AUTOSAR XML (schema 314)
package /ComponentType
  internal behavior Sa_CDDInterface_InternalBehavior: component=Sa_CDDInterface
    5 x timing event:
      CDDInterface_Init1_InitEvent: start-on-event=CDDInterface_Init1, period=0
      CDDInterface_Init2_InitEvent: start-on-event=CDDInterface_Init2, period=0
      TMT_CDDInterface_Per1: start-on-event=CDDInterface_Per1, period=0.002
      TMT_CDDInterface_Per2: start-on-event=CDDInterface_Per2, period=0.002
      TMT_CDDInterface_Per4: start-on-event=CDDInterface_Per4, period=0.01
    operation invoked event OIT_MtrVelCDDInterface_GetMtrVelSignals_MtrVelCDDInterface_GetMtrVelSignals: start-on-event=MtrVelCDDInterface_GetMtrVelSignals, operation=MtrVelCDDInterface.GetMtrVelSignals
    port-api-options:
      enable-take-address=false, indirect-api=false, port=ADCMtrCurr1
      enable-take-address=false, indirect-api=false, port=ADCMtrCurr2
      enable-take-address=false, indirect-api=false, port=CDDPorts
      enable-take-address=false, indirect-api=false, port=CommOffset
      enable-take-address=false, indirect-api=false, port=CorrMtrCurrPosition
      enable-take-address=false, indirect-api=false, port=CorrMtrPosElec
      enable-take-address=false, indirect-api=false, port=Cos1Theta
      enable-take-address=false, indirect-api=false, port=DampingSrlComSvcDft
      enable-take-address=false, indirect-api=false, port=DaxIntegralGain_IPM
      enable-take-address=false, indirect-api=false, port=DaxIntegralGain_SPM
      enable-take-address=false, indirect-api=false, port=DaxPropotionalGain_IPM
      enable-take-address=false, indirect-api=false, port=DaxPropotionalGain_SPM
      enable-take-address=false, indirect-api=false, port=DftAsstTbl
      enable-take-address=false, indirect-api=false, port=DrivingDynSrlComSvcDft
      enable-take-address=false, indirect-api=false, port=DutyCycleSmall
      enable-take-address=false, indirect-api=false, port=DwnldAsstGain
      enable-take-address=false, indirect-api=false, port=EngONSrlComSvcDft
      enable-take-address=false, indirect-api=false, port=EOTImpactSrlComSvcDft
      enable-take-address=false, indirect-api=false, port=EOTThermalSrlComSvcDft
      enable-take-address=false, indirect-api=false, port=EstKe
      enable-take-address=false, indirect-api=false, port=ExpectedOnTimeA
      enable-take-address=false, indirect-api=false, port=ExpectedOnTimeB
      enable-take-address=false, indirect-api=false, port=ExpectedOnTimeC
      enable-take-address=false, indirect-api=false, port=FETFaultPhase
      enable-take-address=false, indirect-api=false, port=FETFaultType
      enable-take-address=false, indirect-api=false, port=FreqDepDmpSrlComSvcDft
      enable-take-address=false, indirect-api=false, port=FricLrnSrlComSvcDft
      enable-take-address=false, indirect-api=false, port=HysAddSrlComSvcDft
      enable-take-address=false, indirect-api=false, port=HystCompSrlComSvcDft
      enable-take-address=false, indirect-api=false, port=IgnCnt
      enable-take-address=false, indirect-api=false, port=KinIntDiagSrlComSvcDft
      enable-take-address=false, indirect-api=false, port=LimitSrlComSvcDft
      enable-take-address=false, indirect-api=false, port=LRPRPhaseadvanceCaptured
      enable-take-address=false, indirect-api=false, port=MeasuredOnTimeA
      enable-take-address=false, indirect-api=false, port=MeasuredOnTimeB
      enable-take-address=false, indirect-api=false, port=MeasuredOnTimeC
      enable-take-address=false, indirect-api=false, port=MEC
      enable-take-address=false, indirect-api=false, port=MfgDiagInhibit
      enable-take-address=false, indirect-api=false, port=ModIdxFinal
      enable-take-address=false, indirect-api=false, port=ModIdxSrlComSvcDft
      enable-take-address=false, indirect-api=false, port=MRFMtrVel
      enable-take-address=false, indirect-api=false, port=MtrCurr1TempOffset
      enable-take-address=false, indirect-api=false, port=MtrCurr2TempOffset
      enable-take-address=false, indirect-api=false, port=MtrCurrDax
      enable-take-address=false, indirect-api=false, port=MtrCurrDaxRef
      enable-take-address=false, indirect-api=false, port=MtrCurrDaxRef_IPM
      enable-take-address=false, indirect-api=false, port=MtrCurrDaxRef_SPM
      enable-take-address=false, indirect-api=false, port=MtrCurrK1
      enable-take-address=false, indirect-api=false, port=MtrCurrK2
      enable-take-address=false, indirect-api=false, port=MtrCurrQax
      enable-take-address=false, indirect-api=false, port=MtrCurrQax12Mag
      enable-take-address=false, indirect-api=false, port=MtrCurrQax12Ph
      enable-take-address=false, indirect-api=false, port=MtrCurrQax6Mag
      enable-take-address=false, indirect-api=false, port=MtrCurrQax6Ph
      enable-take-address=false, indirect-api=false, port=MtrCurrQaxFinalRef
      enable-take-address=false, indirect-api=false, port=MtrCurrQaxRef_IPM
      enable-take-address=false, indirect-api=false, port=MtrCurrQaxRef_SPM
      enable-take-address=false, indirect-api=false, port=MtrElecMechPolarity
      enable-take-address=false, indirect-api=false, port=MtrParmNrmLrnSrlComSvcDft
      enable-take-address=false, indirect-api=false, port=MtrPosComputationDelay_IPM
      enable-take-address=false, indirect-api=false, port=MtrPosComputationDelay_SPM
      enable-take-address=false, indirect-api=false, port=MtrPosElec
      enable-take-address=false, indirect-api=false, port=MtrPosMech
      enable-take-address=false, indirect-api=false, port=MtrRevCntr
      enable-take-address=false, indirect-api=false, port=MtrTrqCmdSign_IPM
      enable-take-address=false, indirect-api=false, port=MtrTrqCmdSign_SPM
      enable-take-address=false, indirect-api=false, port=MtrVelCDDInterface
      enable-take-address=false, indirect-api=false, port=MtrVelNrmLrnSrlComSvcDft
      enable-take-address=false, indirect-api=false, port=MtrVoltDax
      enable-take-address=false, indirect-api=false, port=MtrVoltDaxFF_IPM
      enable-take-address=false, indirect-api=false, port=MtrVoltDaxFF_SPM
      enable-take-address=false, indirect-api=false, port=MtrVoltQax
      enable-take-address=false, indirect-api=false, port=MtrVoltQaxFF_IPM
      enable-take-address=false, indirect-api=false, port=MtrVoltQaxFF_SPM
      enable-take-address=false, indirect-api=false, port=MultIgnSrlComSvcDft
      enable-take-address=false, indirect-api=false, port=ParkAstSrlComSvcDft
      enable-take-address=false, indirect-api=false, port=PhsReasA
      enable-take-address=false, indirect-api=false, port=PhsReasB
      enable-take-address=false, indirect-api=false, port=PhsReasC
      enable-take-address=false, indirect-api=false, port=PullCompSrlComSvcDft
      enable-take-address=false, indirect-api=false, port=QaxIntegralGain_IPM
      enable-take-address=false, indirect-api=false, port=QaxIntegralGain_SPM
      enable-take-address=false, indirect-api=false, port=QaxPropotionalGain_IPM
      enable-take-address=false, indirect-api=false, port=QaxPropotionalGain_SPM
      enable-take-address=false, indirect-api=false, port=ReturnSrlComSvcDft
      enable-take-address=false, indirect-api=false, port=RxMsgsSrlComSvcDft
      enable-take-address=false, indirect-api=false, port=Sin1Theta
      enable-take-address=false, indirect-api=false, port=SrlComSvcDft
      enable-take-address=false, indirect-api=false, port=SWDutyCycleA
      enable-take-address=false, indirect-api=false, port=SWDutyCycleB
      enable-take-address=false, indirect-api=false, port=SWDutyCycleC
      enable-take-address=false, indirect-api=false, port=SysCCorrectedMtrPos
      enable-take-address=false, indirect-api=false, port=SystemState
      enable-take-address=false, indirect-api=false, port=ThermalDCSrlComSvcDft
      enable-take-address=false, indirect-api=false, port=TOEOLDisable
      enable-take-address=false, indirect-api=false, port=TrqRmpSrlComSvcDft
      enable-take-address=false, indirect-api=false, port=Vecu
      enable-take-address=false, indirect-api=false, port=WhlImbRejSrlComSvcDft
      enable-take-address=false, indirect-api=false, port=WIREnabled
    6 x runnable:
      CDDInterface_Init1
        data read access READ_MtrElecMechPolarity_Cnt_s08: data-element=MtrElecMechPolarity.Cnt_s08
        data write access WRITE_IgnCnt_Cnt_u16: data-element=IgnCnt.Cnt_u16
        data write access WRITE_MEC_Cnt_enum: data-element=MEC.Cnt_enum
        sync call SC_CDDPorts_ApplyMtrElecMechPol: operation=CDDPorts.ApplyMtrElecMechPol, timeout=0
      CDDInterface_Init2
      CDDInterface_Per1
        33 x data write access:
          WRITE_ADCMtrCurr1_Volts_f32: data-element=ADCMtrCurr1.Volts_f32
          WRITE_ADCMtrCurr2_Volts_f32: data-element=ADCMtrCurr2.Volts_f32
          WRITE_CorrMtrCurrPosition_Rev_f32: data-element=CorrMtrCurrPosition.Rev_f32
          WRITE_CorrMtrPosElec_Rev_f32: data-element=CorrMtrPosElec.Rev_f32
          WRITE_Cos1Theta_Volts_f32: data-element=Cos1Theta.Volts_f32
          WRITE_DutyCycleSmall_Cnt_u16: data-element=DutyCycleSmall.Cnt_u16
          WRITE_ExpectedOnTimeA_Cnt_u32: data-element=ExpectedOnTimeA.Cnt_u32
          WRITE_ExpectedOnTimeB_Cnt_u32: data-element=ExpectedOnTimeB.Cnt_u32
          WRITE_ExpectedOnTimeC_Cnt_u32: data-element=ExpectedOnTimeC.Cnt_u32
          WRITE_LRPRPhaseadvanceCaptured_Cnt_s16: data-element=LRPRPhaseadvanceCaptured.Cnt_s16
          WRITE_MeasuredOnTimeA_Cnt_u32: data-element=MeasuredOnTimeA.Cnt_u32
          WRITE_MeasuredOnTimeB_Cnt_u32: data-element=MeasuredOnTimeB.Cnt_u32
          WRITE_MeasuredOnTimeC_Cnt_u32: data-element=MeasuredOnTimeC.Cnt_u32
          WRITE_ModIdxFinal_Uls_f32: data-element=ModIdxFinal.Uls_f32
          WRITE_MtrCurrDax_Amp_f32: data-element=MtrCurrDax.Amp_f32
          WRITE_MtrCurrDaxRef_Amp_f32: data-element=MtrCurrDaxRef.Amp_f32
          WRITE_MtrCurrK1_Amp_f32: data-element=MtrCurrK1.Amp_f32
          WRITE_MtrCurrK2_Amp_f32: data-element=MtrCurrK2.Amp_f32
          WRITE_MtrCurrQax_Amp_f32: data-element=MtrCurrQax.Amp_f32
          WRITE_MtrCurrQaxFinalRef_Amp_f32: data-element=MtrCurrQaxFinalRef.Amp_f32
          WRITE_MtrPosElec_Rev_f32: data-element=MtrPosElec.Rev_f32
          WRITE_MtrPosMech_Rev_f32: data-element=MtrPosMech.Rev_f32
          WRITE_MtrRevCntr_Cnt_s16: data-element=MtrRevCntr.Cnt_s16
          WRITE_MtrVoltDax_Volt_f32: data-element=MtrVoltDax.Volt_f32
          WRITE_MtrVoltQax_Volt_f32: data-element=MtrVoltQax.Volt_f32
          WRITE_PhsReasA_Volts_f32: data-element=PhsReasA.Volts_f32
          WRITE_PhsReasB_Volts_f32: data-element=PhsReasB.Volts_f32
          WRITE_PhsReasC_Volts_f32: data-element=PhsReasC.Volts_f32
          WRITE_Sin1Theta_Volts_f32: data-element=Sin1Theta.Volts_f32
          WRITE_SWDutyCycleA_Uls_f32: data-element=SWDutyCycleA.Uls_f32
          WRITE_SWDutyCycleB_Uls_f32: data-element=SWDutyCycleB.Uls_f32
          WRITE_SWDutyCycleC_Uls_f32: data-element=SWDutyCycleC.Uls_f32
          WRITE_SysCCorrectedMtrPos_Rev_f32: data-element=SysCCorrectedMtrPos.Rev_f32
        sync call SC_CDDPorts_ClearPhsReasSum: operation=CDDPorts.ClearPhsReasSum, timeout=0
      CDDInterface_Per2
        30 x data read access:
          READ_CommOffset_Cnt_u16: data-element=CommOffset.Cnt_u16
          READ_DaxIntegralGain_IPM_Uls_f32: data-element=DaxIntegralGain_IPM.Uls_f32
          READ_DaxIntegralGain_SPM_Uls_f32: data-element=DaxIntegralGain_SPM.Uls_f32
          READ_DaxPropotionalGain_IPM_Uls_f32: data-element=DaxPropotionalGain_IPM.Uls_f32
          READ_DaxPropotionalGain_SPM_Uls_f32: data-element=DaxPropotionalGain_SPM.Uls_f32
          READ_EstKe_VpRadpS_f32: data-element=EstKe.VpRadpS_f32
          READ_MRFMtrVel_MtrRadpS_f32: data-element=MRFMtrVel.MtrRadpS_f32
          READ_MtrCurr1TempOffset_Volt_f32: data-element=MtrCurr1TempOffset.Volt_f32
          READ_MtrCurr2TempOffset_Volt_f32: data-element=MtrCurr2TempOffset.Volt_f32
          READ_MtrCurrDaxRef_IPM_Amp_f32: data-element=MtrCurrDaxRef_IPM.Amp_f32
          READ_MtrCurrDaxRef_SPM_Amp_f32: data-element=MtrCurrDaxRef_SPM.Amp_f32
          READ_MtrCurrQax12Mag_Amp_f32: data-element=MtrCurrQax12Mag.Amp_f32
          READ_MtrCurrQax12Ph_Rev_f32: data-element=MtrCurrQax12Ph.Rev_f32
          READ_MtrCurrQax6Mag_Amp_f32: data-element=MtrCurrQax6Mag.Amp_f32
          READ_MtrCurrQax6Ph_Rev_f32: data-element=MtrCurrQax6Ph.Rev_f32
          READ_MtrCurrQaxRef_IPM_Amp_f32: data-element=MtrCurrQaxRef_IPM.Amp_f32
          READ_MtrCurrQaxRef_SPM_Amp_f32: data-element=MtrCurrQaxRef_SPM.Amp_f32
          READ_MtrPosComputationDelay_IPM_Deg_f32: data-element=MtrPosComputationDelay_IPM.Deg_f32
          READ_MtrPosComputationDelay_SPM_Deg_f32: data-element=MtrPosComputationDelay_SPM.Deg_f32
          READ_MtrTrqCmdSign_IPM_Cnt_s16: data-element=MtrTrqCmdSign_IPM.Cnt_s16
          READ_MtrTrqCmdSign_SPM_Cnt_s16: data-element=MtrTrqCmdSign_SPM.Cnt_s16
          READ_MtrVoltDaxFF_IPM_Volt_f32: data-element=MtrVoltDaxFF_IPM.Volt_f32
          READ_MtrVoltDaxFF_SPM_Volt_f32: data-element=MtrVoltDaxFF_SPM.Volt_f32
          READ_MtrVoltQaxFF_IPM_Volt_f32: data-element=MtrVoltQaxFF_IPM.Volt_f32
          READ_MtrVoltQaxFF_SPM_Volt_f32: data-element=MtrVoltQaxFF_SPM.Volt_f32
          READ_QaxIntegralGain_IPM_Uls_f32: data-element=QaxIntegralGain_IPM.Uls_f32
          READ_QaxIntegralGain_SPM_Uls_f32: data-element=QaxIntegralGain_SPM.Uls_f32
          READ_QaxPropotionalGain_IPM_Uls_f32: data-element=QaxPropotionalGain_IPM.Uls_f32
          READ_QaxPropotionalGain_SPM_Uls_f32: data-element=QaxPropotionalGain_SPM.Uls_f32
          READ_Vecu_Volt_f32: data-element=Vecu.Volt_f32
      CDDInterface_Per4
        data read access READ_MtrElecMechPolarity_Cnt_s08: data-element=MtrElecMechPolarity.Cnt_s08
        29 x data write access:
          WRITE_DampingSrlComSvcDft_Cnt_lgc: data-element=DampingSrlComSvcDft.Cnt_lgc
          WRITE_DftAsstTbl_Cnt_lgc: data-element=DftAsstTbl.Cnt_lgc
          WRITE_DrivingDynSrlComSvcDft_Cnt_lgc: data-element=DrivingDynSrlComSvcDft.Cnt_lgc
          WRITE_DwnldAsstGain_Uls_f32: data-element=DwnldAsstGain.Uls_f32
          WRITE_EngONSrlComSvcDft_Cnt_lgc: data-element=EngONSrlComSvcDft.Cnt_lgc
          WRITE_EOTImpactSrlComSvcDft_Cnt_lgc: data-element=EOTImpactSrlComSvcDft.Cnt_lgc
          WRITE_EOTThermalSrlComSvcDft_Cnt_lgc: data-element=EOTThermalSrlComSvcDft.Cnt_lgc
          WRITE_FreqDepDmpSrlComSvcDft_Cnt_lgc: data-element=FreqDepDmpSrlComSvcDft.Cnt_lgc
          WRITE_FricLrnSrlComSvcDft_Cnt_lgc: data-element=FricLrnSrlComSvcDft.Cnt_lgc
          WRITE_HysAddSrlComSvcDft_Cnt_lgc: data-element=HysAddSrlComSvcDft.Cnt_lgc
          WRITE_HystCompSrlComSvcDft_Cnt_lgc: data-element=HystCompSrlComSvcDft.Cnt_lgc
          WRITE_KinIntDiagSrlComSvcDft_Cnt_lgc: data-element=KinIntDiagSrlComSvcDft.Cnt_lgc
          WRITE_LimitSrlComSvcDft_Cnt_lgc: data-element=LimitSrlComSvcDft.Cnt_lgc
          WRITE_MEC_Cnt_enum: data-element=MEC.Cnt_enum
          WRITE_MfgDiagInhibit_Cnt_lgc: data-element=MfgDiagInhibit.Cnt_lgc
          WRITE_ModIdxSrlComSvcDft_Cnt_lgc: data-element=ModIdxSrlComSvcDft.Cnt_lgc
          WRITE_MtrParmNrmLrnSrlComSvcDft_Cnt_lgc: data-element=MtrParmNrmLrnSrlComSvcDft.Cnt_lgc
          WRITE_MtrVelNrmLrnSrlComSvcDft_Cnt_lgc: data-element=MtrVelNrmLrnSrlComSvcDft.Cnt_lgc
          WRITE_MultIgnSrlComSvcDft_Cnt_lgc: data-element=MultIgnSrlComSvcDft.Cnt_lgc
          WRITE_ParkAstSrlComSvcDft_Cnt_lgc: data-element=ParkAstSrlComSvcDft.Cnt_lgc
          WRITE_PullCompSrlComSvcDft_Cnt_lgc: data-element=PullCompSrlComSvcDft.Cnt_lgc
          WRITE_ReturnSrlComSvcDft_Cnt_lgc: data-element=ReturnSrlComSvcDft.Cnt_lgc
          WRITE_RxMsgsSrlComSvcDft_Cnt_lgc: data-element=RxMsgsSrlComSvcDft.Cnt_lgc
          WRITE_SrlComSvcDft_Cnt_b32: data-element=SrlComSvcDft.Cnt_b32
          WRITE_ThermalDCSrlComSvcDft_Cnt_lgc: data-element=ThermalDCSrlComSvcDft.Cnt_lgc
          WRITE_TOEOLDisable_Cnt_lgc: data-element=TOEOLDisable.Cnt_lgc
          WRITE_TrqRmpSrlComSvcDft_Cnt_lgc: data-element=TrqRmpSrlComSvcDft.Cnt_lgc
          WRITE_WhlImbRejSrlComSvcDft_Cnt_lgc: data-element=WhlImbRejSrlComSvcDft.Cnt_lgc
          WRITE_WIREnabled_Cnt_lgc: data-element=WIREnabled.Cnt_lgc
        sync call SC_CDDPorts_ApplyMtrElecMechPol: operation=CDDPorts.ApplyMtrElecMechPol, timeout=0
      MtrVelCDDInterface_GetMtrVelSignals
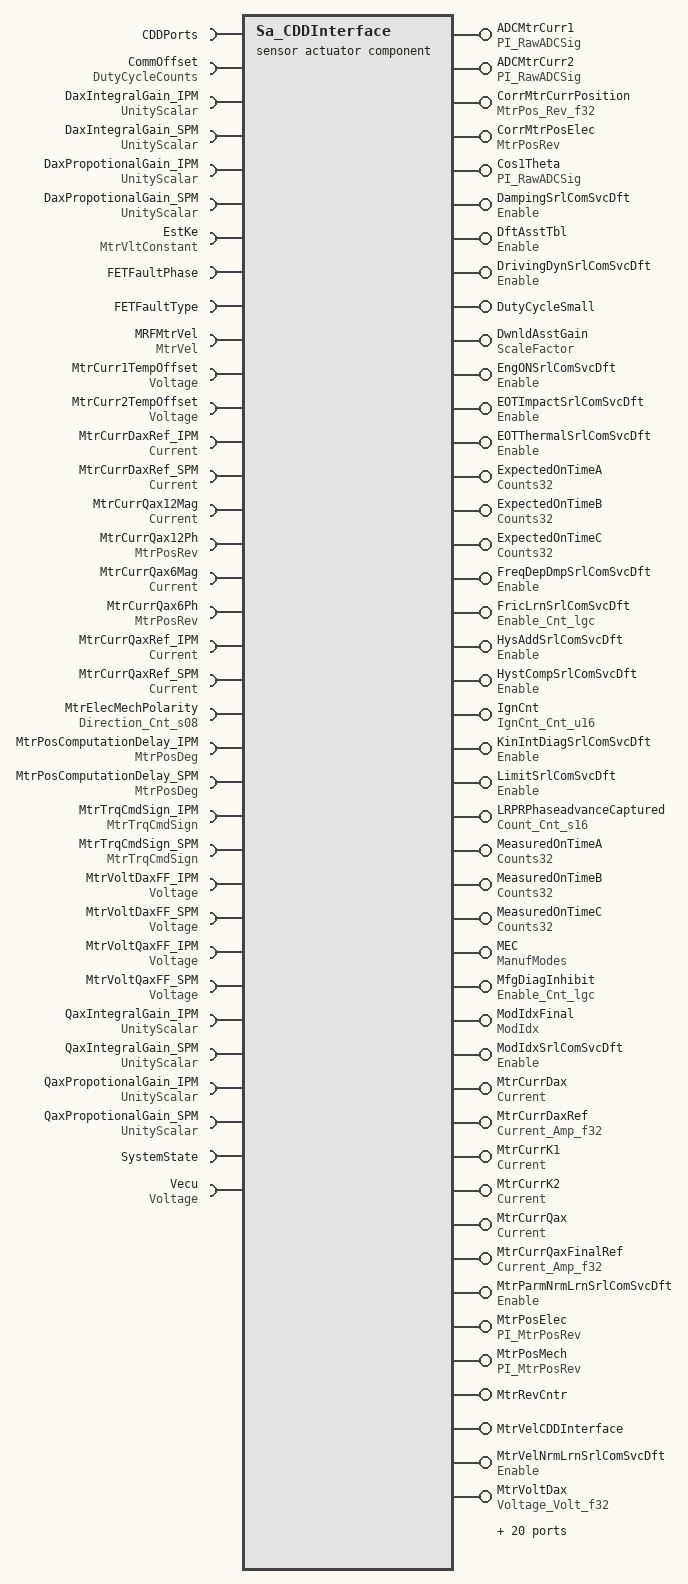
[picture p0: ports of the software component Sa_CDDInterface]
  sensor actuator software component type Sa_CDDInterface
    64 x provide port:
      ADCMtrCurr1: unqueued-sender-com-spec{data-element=Volts_f32, can-invalidate=false, init-value=D_ZERO_ULS_F32}, provided-interface=PI_RawADCSig
      ADCMtrCurr2: unqueued-sender-com-spec{data-element=Volts_f32, can-invalidate=false, init-value=D_ZERO_ULS_F32}, provided-interface=PI_RawADCSig
      CorrMtrCurrPosition: unqueued-sender-com-spec{data-element=Rev_f32, can-invalidate=false, init-value=D_ZERO_ULS_F32}, provided-interface=MtrPos_Rev_f32
      CorrMtrPosElec: unqueued-sender-com-spec{data-element=Rev_f32, can-invalidate=false, init-value=D_ZERO_ULS_F32}, provided-interface=MtrPosRev
      Cos1Theta: unqueued-sender-com-spec{data-element=Volts_f32, can-invalidate=false, init-value=D_ZERO_ULS_F32}, provided-interface=PI_RawADCSig
      DampingSrlComSvcDft: unqueued-sender-com-spec{data-element=Cnt_lgc, can-invalidate=false, init-value=D_FALSE_CNT_LGC}, provided-interface=Enable
      DftAsstTbl: unqueued-sender-com-spec{data-element=Cnt_lgc, can-invalidate=false, init-value=D_FALSE_CNT_LGC}, provided-interface=Enable
      DrivingDynSrlComSvcDft: unqueued-sender-com-spec{data-element=Cnt_lgc, can-invalidate=false, init-value=D_FALSE_CNT_LGC}, provided-interface=Enable
      DutyCycleSmall: unqueued-sender-com-spec{data-element=Cnt_u16, can-invalidate=false, init-value=D_ZERO_CNT_U16}, provided-interface=DutyCycleSmall
      DwnldAsstGain: unqueued-sender-com-spec{data-element=Uls_f32, can-invalidate=false, init-value=D_ZERO_ULS_F32}, provided-interface=ScaleFactor
      EngONSrlComSvcDft: unqueued-sender-com-spec{data-element=Cnt_lgc, can-invalidate=false, init-value=D_FALSE_CNT_LGC}, provided-interface=Enable
      EOTImpactSrlComSvcDft: unqueued-sender-com-spec{data-element=Cnt_lgc, can-invalidate=false, init-value=D_FALSE_CNT_LGC}, provided-interface=Enable
      EOTThermalSrlComSvcDft: unqueued-sender-com-spec{data-element=Cnt_lgc, can-invalidate=false, init-value=D_FALSE_CNT_LGC}, provided-interface=Enable
      ExpectedOnTimeA: unqueued-sender-com-spec{data-element=Cnt_u32, can-invalidate=false, init-value=D_ZERO_CNT_U32}, provided-interface=Counts32
      ExpectedOnTimeB: unqueued-sender-com-spec{data-element=Cnt_u32, can-invalidate=false, init-value=D_ZERO_CNT_U32}, provided-interface=Counts32
      ExpectedOnTimeC: unqueued-sender-com-spec{data-element=Cnt_u32, can-invalidate=false, init-value=D_ZERO_CNT_U32}, provided-interface=Counts32
      FreqDepDmpSrlComSvcDft: unqueued-sender-com-spec{data-element=Cnt_lgc, can-invalidate=false, init-value=D_FALSE_CNT_LGC}, provided-interface=Enable
      FricLrnSrlComSvcDft: unqueued-sender-com-spec{data-element=Cnt_lgc, can-invalidate=false, init-value=D_FALSE_CNT_LGC}, provided-interface=Enable_Cnt_lgc
      HysAddSrlComSvcDft: unqueued-sender-com-spec{data-element=Cnt_lgc, can-invalidate=false, init-value=D_FALSE_CNT_LGC}, provided-interface=Enable
      HystCompSrlComSvcDft: unqueued-sender-com-spec{data-element=Cnt_lgc, can-invalidate=false, init-value=D_FALSE_CNT_LGC}, provided-interface=Enable
      IgnCnt: unqueued-sender-com-spec{data-element=Cnt_u16, can-invalidate=false, init-value=D_ZERO_CNT_U16}, provided-interface=IgnCnt_Cnt_u16
      KinIntDiagSrlComSvcDft: unqueued-sender-com-spec{data-element=Cnt_lgc, can-invalidate=false, init-value=D_FALSE_CNT_LGC}, provided-interface=Enable
      LimitSrlComSvcDft: unqueued-sender-com-spec{data-element=Cnt_lgc, can-invalidate=false, init-value=D_FALSE_CNT_LGC}, provided-interface=Enable
      LRPRPhaseadvanceCaptured: unqueued-sender-com-spec{data-element=Cnt_s16, can-invalidate=false, init-value=D_ZERO_CNT_S16}, provided-interface=Count_Cnt_s16
      MeasuredOnTimeA: unqueued-sender-com-spec{data-element=Cnt_u32, can-invalidate=false, init-value=D_ZERO_CNT_U32}, provided-interface=Counts32
      MeasuredOnTimeB: unqueued-sender-com-spec{data-element=Cnt_u32, can-invalidate=false, init-value=D_ZERO_CNT_U32}, provided-interface=Counts32
      MeasuredOnTimeC: unqueued-sender-com-spec{data-element=Cnt_u32, can-invalidate=false, init-value=D_ZERO_CNT_U32}, provided-interface=Counts32
      MEC: unqueued-sender-com-spec{data-element=Cnt_enum, can-invalidate=false, init-value=D_MANUFMODEINIT_CNT_ENUM}, provided-interface=ManufModes
      MfgDiagInhibit: unqueued-sender-com-spec{data-element=Cnt_lgc, can-invalidate=false, init-value=D_FALSE_CNT_LGC}, provided-interface=Enable_Cnt_lgc
      ModIdxFinal: unqueued-sender-com-spec{data-element=Uls_f32, can-invalidate=false, init-value=D_ZERO_ULS_F32}, provided-interface=ModIdx
      ModIdxSrlComSvcDft: unqueued-sender-com-spec{data-element=Cnt_lgc, can-invalidate=false, init-value=D_FALSE_CNT_LGC}, provided-interface=Enable
      MtrCurrDax: unqueued-sender-com-spec{data-element=Amp_f32, can-invalidate=false, init-value=D_ZERO_ULS_F32}, provided-interface=Current
      MtrCurrDaxRef: unqueued-sender-com-spec{data-element=Amp_f32, can-invalidate=false, init-value=D_ZERO_ULS_F32}, provided-interface=Current_Amp_f32
      MtrCurrK1: unqueued-sender-com-spec{data-element=Amp_f32, can-invalidate=false, init-value=D_ZERO_ULS_F32}, provided-interface=Current
      MtrCurrK2: unqueued-sender-com-spec{data-element=Amp_f32, can-invalidate=false, init-value=D_ZERO_ULS_F32}, provided-interface=Current
      MtrCurrQax: unqueued-sender-com-spec{data-element=Amp_f32, can-invalidate=false, init-value=D_ZERO_ULS_F32}, provided-interface=Current
      MtrCurrQaxFinalRef: unqueued-sender-com-spec{data-element=Amp_f32, can-invalidate=false, init-value=D_ZERO_ULS_F32}, provided-interface=Current_Amp_f32
      MtrParmNrmLrnSrlComSvcDft: unqueued-sender-com-spec{data-element=Cnt_lgc, can-invalidate=false, init-value=D_FALSE_CNT_LGC}, provided-interface=Enable
      MtrPosElec: unqueued-sender-com-spec{data-element=Rev_f32, can-invalidate=false, init-value=D_ZERO_ULS_F32}, provided-interface=PI_MtrPosRev
      MtrPosMech: unqueued-sender-com-spec{data-element=Rev_f32, can-invalidate=false, init-value=D_ZERO_ULS_F32}, provided-interface=PI_MtrPosRev
      MtrRevCntr: unqueued-sender-com-spec{data-element=Cnt_s16, can-invalidate=false, init-value=D_ZERO_CNT_S16}, provided-interface=MtrRevCntr
      MtrVelCDDInterface: server-com-spec{operation=GetMtrVelSignals, queue-length=1}, provided-interface=MtrVelCDDInterface
      MtrVelNrmLrnSrlComSvcDft: unqueued-sender-com-spec{data-element=Cnt_lgc, can-invalidate=false, init-value=D_FALSE_CNT_LGC}, provided-interface=Enable
      MtrVoltDax: unqueued-sender-com-spec{data-element=Volt_f32, can-invalidate=false, init-value=D_ZERO_ULS_F32}, provided-interface=Voltage_Volt_f32
      MtrVoltQax: unqueued-sender-com-spec{data-element=Volt_f32, can-invalidate=false, init-value=D_ZERO_ULS_F32}, provided-interface=Voltage_Volt_f32
      MultIgnSrlComSvcDft: unqueued-sender-com-spec{data-element=Cnt_lgc, can-invalidate=false, init-value=D_FALSE_CNT_LGC}, provided-interface=Enable
      ParkAstSrlComSvcDft: unqueued-sender-com-spec{data-element=Cnt_lgc, can-invalidate=false, init-value=D_FALSE_CNT_LGC}, provided-interface=Enable
      PhsReasA: unqueued-sender-com-spec{data-element=Volts_f32, can-invalidate=false, init-value=D_ZERO_ULS_F32}, provided-interface=PhsReas
      PhsReasB: unqueued-sender-com-spec{data-element=Volts_f32, can-invalidate=false, init-value=D_ZERO_ULS_F32}, provided-interface=PhsReas
      PhsReasC: unqueued-sender-com-spec{data-element=Volts_f32, can-invalidate=false, init-value=D_ZERO_ULS_F32}, provided-interface=PhsReas
      PullCompSrlComSvcDft: unqueued-sender-com-spec{data-element=Cnt_lgc, can-invalidate=false, init-value=D_FALSE_CNT_LGC}, provided-interface=Enable
      ReturnSrlComSvcDft: unqueued-sender-com-spec{data-element=Cnt_lgc, can-invalidate=false, init-value=D_FALSE_CNT_LGC}, provided-interface=Enable
      RxMsgsSrlComSvcDft: unqueued-sender-com-spec{data-element=Cnt_lgc, can-invalidate=false, init-value=D_FALSE_CNT_LGC}, provided-interface=Enable
      Sin1Theta: unqueued-sender-com-spec{data-element=Volts_f32, can-invalidate=false, init-value=D_ZERO_ULS_F32}, provided-interface=PI_RawADCSig
      SrlComSvcDft: unqueued-sender-com-spec{data-element=Cnt_b32, can-invalidate=false, init-value=D_ZERO_CNT_U32}, provided-interface=SrlComSvcDft
      SWDutyCycleA: unqueued-sender-com-spec{data-element=Uls_f32, can-invalidate=false, init-value=D_ZERO_ULS_F32}, provided-interface=SWDutyCycle
      SWDutyCycleB: unqueued-sender-com-spec{data-element=Uls_f32, can-invalidate=false, init-value=D_ZERO_ULS_F32}, provided-interface=SWDutyCycle
      SWDutyCycleC: unqueued-sender-com-spec{data-element=Uls_f32, can-invalidate=false, init-value=D_ZERO_ULS_F32}, provided-interface=SWDutyCycle
      SysCCorrectedMtrPos: unqueued-sender-com-spec{data-element=Rev_f32, can-invalidate=false, init-value=D_ZERO_ULS_F32}, provided-interface=MtrPos_Rev_f32
      ThermalDCSrlComSvcDft: unqueued-sender-com-spec{data-element=Cnt_lgc, can-invalidate=false, init-value=D_FALSE_CNT_LGC}, provided-interface=Enable
      TOEOLDisable: unqueued-sender-com-spec{data-element=Cnt_lgc, can-invalidate=false, init-value=D_FALSE_CNT_LGC}, provided-interface=BoolStatusFlag_Cnt_lgc
      TrqRmpSrlComSvcDft: unqueued-sender-com-spec{data-element=Cnt_lgc, can-invalidate=false, init-value=D_FALSE_CNT_LGC}, provided-interface=Enable
      WhlImbRejSrlComSvcDft: unqueued-sender-com-spec{data-element=Cnt_lgc, can-invalidate=false, init-value=D_FALSE_CNT_LGC}, provided-interface=Enable
      WIREnabled: unqueued-sender-com-spec{data-element=Cnt_lgc, can-invalidate=false, init-value=D_FALSE_CNT_LGC}, provided-interface=Enable
    35 x require port:
      CDDPorts: required-com-specs=[ApplyMtrElecMechPol, ClearPhsReasSum], required-interface=CDDPorts
      CommOffset: unqueued-receiver-com-spec{data-element=Cnt_u16, init-value=D_ZERO_CNT_U16}, required-interface=DutyCycleCounts
      DaxIntegralGain_IPM: unqueued-receiver-com-spec{data-element=Uls_f32, init-value=D_ZERO_ULS_F32}, required-interface=UnityScalar
      DaxIntegralGain_SPM: unqueued-receiver-com-spec{data-element=Uls_f32, init-value=D_ZERO_ULS_F32}, required-interface=UnityScalar
      DaxPropotionalGain_IPM: unqueued-receiver-com-spec{data-element=Uls_f32, init-value=D_ZERO_ULS_F32}, required-interface=UnityScalar
      DaxPropotionalGain_SPM: unqueued-receiver-com-spec{data-element=Uls_f32, init-value=D_ZERO_ULS_F32}, required-interface=UnityScalar
      EstKe: unqueued-receiver-com-spec{data-element=VpRadpS_f32, init-value=D_ZERO_ULS_F32}, required-interface=MtrVltConstant
      FETFaultPhase: unqueued-receiver-com-spec{data-element=Cnt_enum, init-value=D_FETFAULTPHASEINIT_CNT_ENUM}, required-interface=FETFaultPhase
      FETFaultType: unqueued-receiver-com-spec{data-element=Cnt_enum, init-value=D_FETFAULTTYPEINIT_CNT_ENUM}, required-interface=FETFaultType
      MRFMtrVel: unqueued-receiver-com-spec{data-element=MtrRadpS_f32, init-value=D_ZERO_ULS_F32}, required-interface=MtrVel
      MtrCurr1TempOffset: unqueued-receiver-com-spec{data-element=Volt_f32, init-value=D_ZERO_ULS_F32}, required-interface=Voltage
      MtrCurr2TempOffset: unqueued-receiver-com-spec{data-element=Volt_f32, init-value=D_ZERO_ULS_F32}, required-interface=Voltage
      MtrCurrDaxRef_IPM: unqueued-receiver-com-spec{data-element=Amp_f32, init-value=D_ZERO_ULS_F32}, required-interface=Current
      MtrCurrDaxRef_SPM: unqueued-receiver-com-spec{data-element=Amp_f32, init-value=D_ZERO_ULS_F32}, required-interface=Current
      MtrCurrQax12Mag: unqueued-receiver-com-spec{data-element=Amp_f32, init-value=D_ZERO_ULS_F32}, required-interface=Current
      MtrCurrQax12Ph: unqueued-receiver-com-spec{data-element=Rev_f32, init-value=D_ZERO_ULS_F32}, required-interface=MtrPosRev
      MtrCurrQax6Mag: unqueued-receiver-com-spec{data-element=Amp_f32, init-value=D_ZERO_ULS_F32}, required-interface=Current
      MtrCurrQax6Ph: unqueued-receiver-com-spec{data-element=Rev_f32, init-value=D_ZERO_ULS_F32}, required-interface=MtrPosRev
      MtrCurrQaxRef_IPM: unqueued-receiver-com-spec{data-element=Amp_f32, init-value=D_ZERO_ULS_F32}, required-interface=Current
      MtrCurrQaxRef_SPM: unqueued-receiver-com-spec{data-element=Amp_f32, init-value=D_ZERO_ULS_F32}, required-interface=Current
      MtrElecMechPolarity: unqueued-receiver-com-spec{data-element=Cnt_s08, init-value=D_ZERO_CNT_S8}, required-interface=Direction_Cnt_s08
      MtrPosComputationDelay_IPM: unqueued-receiver-com-spec{data-element=Deg_f32, init-value=D_ZERO_ULS_F32}, required-interface=MtrPosDeg
      MtrPosComputationDelay_SPM: unqueued-receiver-com-spec{data-element=Deg_f32, init-value=D_ZERO_ULS_F32}, required-interface=MtrPosDeg
      MtrTrqCmdSign_IPM: unqueued-receiver-com-spec{data-element=Cnt_s16, init-value=D_ZERO_CNT_S16}, required-interface=MtrTrqCmdSign
      MtrTrqCmdSign_SPM: unqueued-receiver-com-spec{data-element=Cnt_s16, init-value=D_ZERO_CNT_S16}, required-interface=MtrTrqCmdSign
      MtrVoltDaxFF_IPM: unqueued-receiver-com-spec{data-element=Volt_f32, init-value=D_ZERO_ULS_F32}, required-interface=Voltage
      MtrVoltDaxFF_SPM: unqueued-receiver-com-spec{data-element=Volt_f32, init-value=D_ZERO_ULS_F32}, required-interface=Voltage
      MtrVoltQaxFF_IPM: unqueued-receiver-com-spec{data-element=Volt_f32, init-value=D_ZERO_ULS_F32}, required-interface=Voltage
      MtrVoltQaxFF_SPM: unqueued-receiver-com-spec{data-element=Volt_f32, init-value=D_ZERO_ULS_F32}, required-interface=Voltage
      QaxIntegralGain_IPM: unqueued-receiver-com-spec{data-element=Uls_f32, init-value=D_ZERO_ULS_F32}, required-interface=UnityScalar
      QaxIntegralGain_SPM: unqueued-receiver-com-spec{data-element=Uls_f32, init-value=D_ZERO_ULS_F32}, required-interface=UnityScalar
      QaxPropotionalGain_IPM: unqueued-receiver-com-spec{data-element=Uls_f32, init-value=D_ZERO_ULS_F32}, required-interface=UnityScalar
      QaxPropotionalGain_SPM: unqueued-receiver-com-spec{data-element=Uls_f32, init-value=D_ZERO_ULS_F32}, required-interface=UnityScalar
      SystemState: required-interface=SystemState
      Vecu: unqueued-receiver-com-spec{data-element=Volt_f32, init-value=D_VECUMIN_VOLTS_F32}, required-interface=Voltage
  swc implementation Sa_CDDInterface_Implementation: behavior=Sa_CDDInterface_InternalBehavior
    code-descriptors:
      code Code: type=SRC
